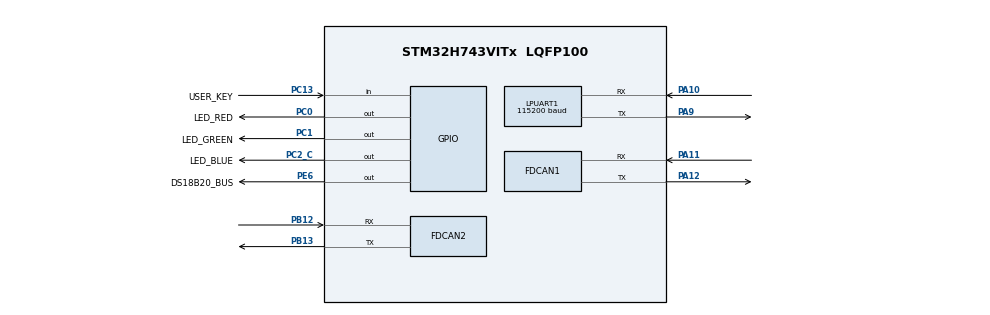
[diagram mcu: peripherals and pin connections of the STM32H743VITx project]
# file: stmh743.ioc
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ADC3.Channel-2\#ChannelRegularConversion=ADC_CHANNEL_TEMPSENSOR
ADC3.NbrOfConversion=1
ADC3.NbrOfConversionFlag=1
ADC3.OffsetNumber-2\#ChannelRegularConversion=ADC_OFFSET_NONE
ADC3.OffsetSignedSaturation-2\#ChannelRegularConversion=DISABLE
ADC3.Rank-2\#ChannelRegularConversion=1
ADC3.SamplingTime-2\#ChannelRegularConversion=ADC_SAMPLETIME_810CYCLES_5
Bdma.LPUART1_RX.1.Direction=DMA_PERIPH_TO_MEMORY
Bdma.LPUART1_RX.1.EventEnable=DISABLE
Bdma.LPUART1_RX.1.Instance=BDMA_Channel1
Bdma.LPUART1_RX.1.MemDataAlignment=DMA_MDATAALIGN_BYTE
Bdma.LPUART1_RX.1.MemInc=DMA_MINC_ENABLE
Bdma.LPUART1_RX.1.Mode=DMA_CIRCULAR
Bdma.LPUART1_RX.1.PeriphDataAlignment=DMA_PDATAALIGN_BYTE
Bdma.LPUART1_RX.1.PeriphInc=DMA_PINC_DISABLE
Bdma.LPUART1_RX.1.Polarity=HAL_DMAMUX_REQ_GEN_RISING
Bdma.LPUART1_RX.1.Priority=DMA_PRIORITY_LOW
Bdma.LPUART1_RX.1.RequestNumber=1
Bdma.LPUART1_RX.1.SignalID=NONE
Bdma.LPUART1_RX.1.SyncEnable=DISABLE
Bdma.LPUART1_RX.1.SyncPolarity=HAL_DMAMUX_SYNC_NO_EVENT
Bdma.LPUART1_RX.1.SyncRequestNumber=1
Bdma.LPUART1_RX.1.SyncSignalID=NONE
Bdma.LPUART1_TX.0.Direction=DMA_MEMORY_TO_PERIPH
Bdma.LPUART1_TX.0.EventEnable=DISABLE
Bdma.LPUART1_TX.0.Instance=BDMA_Channel0
Bdma.LPUART1_TX.0.MemDataAlignment=DMA_MDATAALIGN_BYTE
Bdma.LPUART1_TX.0.MemInc=DMA_MINC_ENABLE
Bdma.LPUART1_TX.0.Mode=DMA_NORMAL
Bdma.LPUART1_TX.0.PeriphDataAlignment=DMA_PDATAALIGN_BYTE
Bdma.LPUART1_TX.0.PeriphInc=DMA_PINC_DISABLE
Bdma.LPUART1_TX.0.Polarity=HAL_DMAMUX_REQ_GEN_RISING
Bdma.LPUART1_TX.0.Priority=DMA_PRIORITY_LOW
Bdma.LPUART1_TX.0.RequestNumber=1
Bdma.LPUART1_TX.0.SignalID=NONE
Bdma.LPUART1_TX.0.SyncEnable=DISABLE
Bdma.LPUART1_TX.0.SyncPolarity=HAL_DMAMUX_SYNC_NO_EVENT
Bdma.LPUART1_TX.0.SyncRequestNumber=1
Bdma.LPUART1_TX.0.SyncSignalID=NONE
Bdma.Request0=LPUART1_TX
Bdma.Request1=LPUART1_RX
Bdma.RequestsNb=2
CORTEX_M7.default_mode_Activation=1
FDCAN1.CalculateBaudRateNominal=500000
FDCAN1.CalculateTimeBitNominal=2000
FDCAN1.CalculateTimeQuantumNominal=400.0
FDCAN1.NominalPrescaler=50
FDCAN1.NominalTimeSeg1=2
FDCAN1.NominalTimeSeg2=2
FDCAN1.TxBuffersNbr=32
FDCAN2.CalculateBaudRateNominal=500000
FDCAN2.CalculateTimeBitNominal=2000
FDCAN2.CalculateTimeQuantumNominal=400.0
FDCAN2.NominalPrescaler=50
FDCAN2.NominalTimeSeg1=2
FDCAN2.NominalTimeSeg2=2
FDCAN2.TxBuffersNbr=32
FREERTOS.Tasks01=defaultTask,24,128,StartDefaultTask,Default,NULL,Dynamic,NULL,NULL
LPUART1.BaudRate=115200
Mcu.Family=STM32H7
Mcu.Name=STM32H743VITx
Mcu.Package=LQFP100
NVIC.BDMA_Channel0_IRQn=true\:5\:0\:false\:false\:true\:true\:false\:true\:true
NVIC.BDMA_Channel1_IRQn=true\:5\:0\:false\:false\:true\:true\:false\:true\:true
NVIC.LPUART1_IRQn=true\:5\:0\:false\:false\:true\:true\:true\:true\:true
NVIC.PriorityGroup=NVIC_PRIORITYGROUP_4
NVIC.TIM7_IRQn=true\:15\:0\:false\:false\:true\:false\:false\:true\:true
NVIC.TimeBase=TIM7_IRQn
NVIC.TimeBaseIP=TIM7
PA10.Mode=Asynchronous
PA10.Signal=LPUART1_RX
PA11.Mode=FDCAN_Activate
PA11.Signal=FDCAN1_RX
PA12.Mode=FDCAN_Activate
PA12.Signal=FDCAN1_TX
PA13\ (JTMS/SWDIO).Mode=Serial_Wire
PA13\ (JTMS/SWDIO).Signal=DEBUG_JTMS-SWDIO
PA14\ (JTCK/SWCLK).Mode=Serial_Wire
PA14\ (JTCK/SWCLK).Signal=DEBUG_JTCK-SWCLK
PA9.Mode=Asynchronous
PA9.Signal=LPUART1_TX
PB12.Mode=FDCAN_Activate
PB12.Signal=FDCAN2_RX
PB13.Mode=FDCAN_Activate
PB13.Signal=FDCAN2_TX
PC0.GPIO_Label=LED_RED
PC0.PinState=GPIO_PIN_SET
PC0.Signal=GPIO_Output
PC1.GPIO_Label=LED_GREEN
PC1.PinState=GPIO_PIN_SET
PC1.Signal=GPIO_Output
PC13.GPIO_Label=USER_KEY
PC13.GPIO_PuPd=GPIO_PULLUP
PC13.Signal=GPIO_Input
PC14-OSC32_IN\ (OSC32_IN).Mode=LSE-External-Oscillator
PC14-OSC32_IN\ (OSC32_IN).Signal=RCC_OSC32_IN
PC15-OSC32_OUT\ (OSC32_OUT).Mode=LSE-External-Oscillator
PC15-OSC32_OUT\ (OSC32_OUT).Signal=RCC_OSC32_OUT
PC2_C.GPIO_Label=LED_BLUE
PC2_C.PinState=GPIO_PIN_SET
PC2_C.Signal=GPIO_Output
PE6.GPIO_Label=DS18B20_BUS
PE6.GPIO_ModeDefaultOutputPP=GPIO_MODE_OUTPUT_OD
PE6.GPIO_PuPd=GPIO_PULLUP
PE6.PinState=GPIO_PIN_SET
PE6.Signal=GPIO_Output
PH0-OSC_IN\ (PH0).Mode=HSE-External-Oscillator
PH0-OSC_IN\ (PH0).Signal=RCC_OSC_IN
PH1-OSC_OUT\ (PH1).Mode=HSE-External-Oscillator
PH1-OSC_OUT\ (PH1).Signal=RCC_OSC_OUT
ProjectManager.HeapSize=0x200
ProjectManager.StackSize=0x400
ProjectManager.TargetToolchain=CMake
RCC.ADCFreq_Value=100000000
RCC.APB1Freq_Value=120000000
RCC.APB2Freq_Value=120000000
RCC.APB3Freq_Value=120000000
RCC.APB4Freq_Value=120000000
RCC.CortexFreq_Value=480000000
RCC.D1PPRE=RCC_APB3_DIV2
RCC.D2PPRE1=RCC_APB1_DIV2
RCC.D2PPRE2=RCC_APB2_DIV2
RCC.D3PPRE=RCC_APB4_DIV2
RCC.DIVM1=5
RCC.DIVM2=5
RCC.DIVN1=192
RCC.DIVN2=100
RCC.DIVP2=5
RCC.DIVQ2=4
RCC.DIVQ3=1
RCC.FDCANCLockSelection=RCC_FDCANCLKSOURCE_PLL2
RCC.HCLKFreq_Value=240000000
RCC.HPRE=RCC_HCLK_DIV2
RCC.PLLSourceVirtual=RCC_PLLSOURCE_HSE
RCC.SYSCLKFreq_VALUE=480000000
RCC.SYSCLKSource=RCC_SYSCLKSOURCE_PLLCLK
RCC.USBFreq_Value=480000000
VP_ADC3_TempSens_Input.Mode=IN-TempSens
VP_FREERTOS_VS_CMSIS_V2.Mode=CMSIS_V2
VP_MEMORYMAP_VS_MEMORYMAP.Mode=CurAppReg
VP_SYS_VS_tim7.Mode=TIM7
VP_TIM2_VS_ClockSourceINT.Mode=Internal
board=custom

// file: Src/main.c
/* USER CODE BEGIN Header */
/**
 ******************************************************************************
 * @file           : main.c
 * @brief          : Main program body
 ******************************************************************************
 * @attention
 *
 * Copyright (c) 2026 STMicroelectronics.
 * All rights reserved.
 *
 * This software is licensed under terms that can be found in the LICENSE file
 * in the root directory of this software component.
 * If no LICENSE file comes with this software, it is provided AS-IS.
 *
 ******************************************************************************
 */
/* USER CODE END Header */
#include "main.h"
#include "cmsis_os.h"
#include "adc.h"
#include "bdma.h"
#include "fdcan.h"
#include "usart.h"
#include "tim.h"
#include "gpio.h"

/* USER CODE BEGIN Includes */
#include <elog.h>
#include <hal_uart.h>
#include <user_main.h>

#include "dwt_count.h"
/* USER CODE END Includes */

void SystemClock_Config(void);
void PeriphCommonClock_Config(void);
static void MPU_Config(void);
void MX_FREERTOS_Init(void);

int main(void)
{

  /* MPU Configuration--------------------------------------------------------*/
  MPU_Config();

  /* MCU Configuration--------------------------------------------------------*/

  /* Reset of all peripherals, Initializes the Flash interface and the Systick. */
  HAL_Init();

  /* Configure the system clock */
  SystemClock_Config();

  /* Configure the peripherals common clocks */
  PeriphCommonClock_Config();

  /* USER CODE BEGIN SysInit */
    dwt_delay_init();

  /* USER CODE END SysInit */

  /* Initialize all configured peripherals */
  MX_GPIO_Init();
  MX_BDMA_Init();
  MX_LPUART1_UART_Init();
  MX_ADC3_Init();
  MX_FDCAN1_Init();
  MX_FDCAN2_Init();
  MX_TIM2_Init();
  /* USER CODE BEGIN 2 */
    hal_uart_init();
    elog_init();
    elog_start();
    (void) xTaskCreate(user_main, "user main", 1 * 1024, NULL, 1, NULL);
  /* USER CODE END 2 */

  /* Init scheduler */
  osKernelInitialize();  /* Call init function for freertos objects (in cmsis_os2.c) */
  MX_FREERTOS_Init();

  /* Start scheduler */
  osKernelStart();

  /* We should never get here as control is now taken by the scheduler */

  /* Infinite loop */
    while (1) {

    }
}

void SystemClock_Config(void)
{
  RCC_OscInitTypeDef RCC_OscInitStruct = {0};
  RCC_ClkInitTypeDef RCC_ClkInitStruct = {0};

  /** Supply configuration update enable
  */
  HAL_PWREx_ConfigSupply(PWR_LDO_SUPPLY);

  /** Configure the main internal regulator output voltage
  */
  __HAL_PWR_VOLTAGESCALING_CONFIG(PWR_REGULATOR_VOLTAGE_SCALE0);

  while(!__HAL_PWR_GET_FLAG(PWR_FLAG_VOSRDY)) {}

  /** Initializes the RCC Oscillators according to the specified parameters
  * in the RCC_OscInitTypeDef structure.
  */
  RCC_OscInitStruct.OscillatorType = RCC_OSCILLATORTYPE_HSE;
  RCC_OscInitStruct.HSEState = RCC_HSE_ON;
  RCC_OscInitStruct.PLL.PLLState = RCC_PLL_ON;
  RCC_OscInitStruct.PLL.PLLSource = RCC_PLLSOURCE_HSE;
  RCC_OscInitStruct.PLL.PLLM = 5;
  RCC_OscInitStruct.PLL.PLLN = 192;
  RCC_OscInitStruct.PLL.PLLP = 2;
  RCC_OscInitStruct.PLL.PLLQ = 2;
  RCC_OscInitStruct.PLL.PLLR = 2;
  RCC_OscInitStruct.PLL.PLLRGE = RCC_PLL1VCIRANGE_2;
  RCC_OscInitStruct.PLL.PLLVCOSEL = RCC_PLL1VCOWIDE;
  RCC_OscInitStruct.PLL.PLLFRACN = 0;
  if (HAL_RCC_OscConfig(&RCC_OscInitStruct) != HAL_OK)
  {
    Error_Handler();
  }

  /** Initializes the CPU, AHB and APB buses clocks
  */
  RCC_ClkInitStruct.ClockType = RCC_CLOCKTYPE_HCLK|RCC_CLOCKTYPE_SYSCLK
                              |RCC_CLOCKTYPE_PCLK1|RCC_CLOCKTYPE_PCLK2
                              |RCC_CLOCKTYPE_D3PCLK1|RCC_CLOCKTYPE_D1PCLK1;
  RCC_ClkInitStruct.SYSCLKSource = RCC_SYSCLKSOURCE_PLLCLK;
  RCC_ClkInitStruct.SYSCLKDivider = RCC_SYSCLK_DIV1;
  RCC_ClkInitStruct.AHBCLKDivider = RCC_HCLK_DIV2;
  RCC_ClkInitStruct.APB3CLKDivider = RCC_APB3_DIV2;
  RCC_ClkInitStruct.APB1CLKDivider = RCC_APB1_DIV2;
  RCC_ClkInitStruct.APB2CLKDivider = RCC_APB2_DIV2;
  RCC_ClkInitStruct.APB4CLKDivider = RCC_APB4_DIV2;

  if (HAL_RCC_ClockConfig(&RCC_ClkInitStruct, FLASH_LATENCY_4) != HAL_OK)
  {
    Error_Handler();
  }
}

void PeriphCommonClock_Config(void)
{
  RCC_PeriphCLKInitTypeDef PeriphClkInitStruct = {0};

  /** Initializes the peripherals clock
  */
  PeriphClkInitStruct.PeriphClockSelection = RCC_PERIPHCLK_ADC|RCC_PERIPHCLK_FDCAN;
  PeriphClkInitStruct.PLL2.PLL2M = 5;
  PeriphClkInitStruct.PLL2.PLL2N = 100;
  PeriphClkInitStruct.PLL2.PLL2P = 5;
  PeriphClkInitStruct.PLL2.PLL2Q = 4;
  PeriphClkInitStruct.PLL2.PLL2R = 2;
  PeriphClkInitStruct.PLL2.PLL2RGE = RCC_PLL2VCIRANGE_2;
  PeriphClkInitStruct.PLL2.PLL2VCOSEL = RCC_PLL2VCOWIDE;
  PeriphClkInitStruct.PLL2.PLL2FRACN = 0;
  PeriphClkInitStruct.FdcanClockSelection = RCC_FDCANCLKSOURCE_PLL2;
  PeriphClkInitStruct.AdcClockSelection = RCC_ADCCLKSOURCE_PLL2;
  if (HAL_RCCEx_PeriphCLKConfig(&PeriphClkInitStruct) != HAL_OK)
  {
    Error_Handler();
  }
}

 /* MPU Configuration */

void MPU_Config(void)
{
  MPU_Region_InitTypeDef MPU_InitStruct = {0};

  /* Disables the MPU */
  HAL_MPU_Disable();

  /** Initializes and configures the Region and the memory to be protected
  */
  MPU_InitStruct.Enable = MPU_REGION_ENABLE;
  MPU_InitStruct.Number = MPU_REGION_NUMBER0;
  MPU_InitStruct.BaseAddress = 0x0;
  MPU_InitStruct.Size = MPU_REGION_SIZE_4GB;
  MPU_InitStruct.SubRegionDisable = 0x87;
  MPU_InitStruct.TypeExtField = MPU_TEX_LEVEL0;
  MPU_InitStruct.AccessPermission = MPU_REGION_NO_ACCESS;
  MPU_InitStruct.DisableExec = MPU_INSTRUCTION_ACCESS_DISABLE;
  MPU_InitStruct.IsShareable = MPU_ACCESS_SHAREABLE;
  MPU_InitStruct.IsCacheable = MPU_ACCESS_NOT_CACHEABLE;
  MPU_InitStruct.IsBufferable = MPU_ACCESS_NOT_BUFFERABLE;

  HAL_MPU_ConfigRegion(&MPU_InitStruct);
  /* Enables the MPU */
  HAL_MPU_Enable(MPU_PRIVILEGED_DEFAULT);

}

void HAL_TIM_PeriodElapsedCallback(TIM_HandleTypeDef *htim)
{
  if (htim->Instance == TIM7)
  {
    HAL_IncTick();
  }
}

void Error_Handler(void)
{
    __disable_irq();
    while (1) {
    }
}
